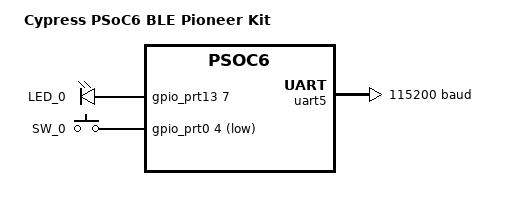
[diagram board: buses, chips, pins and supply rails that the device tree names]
/*
 * Copyright (c) 2018, Cypress
 * Copyright (c) 2020, ATL Electronics
 *
 * SPDX-License-Identifier: Apache-2.0
 */

/dts-v1/;

#include <cypress/psoc6_cm0.dtsi>

/ {
	model = "Cypress PSoC6 BLE Pioneer Kit";
	compatible = "cypress,cy8c6xx7_cm0p", "cypress,psoc6";

	aliases {
		sw0 = &user_bt;
		led0 = &user_led;
		uart-5 = &uart5;
	};

	chosen {
		zephyr,sram = &sram0;
		zephyr,flash = &flash0;
		zephyr,console = &uart5;
		zephyr,shell-uart = &uart5;
	};

	leds {
		compatible = "gpio-leds";
		user_led: led_0 {
			label = "LED_0";
			gpios = <&gpio_prt13 7 GPIO_ACTIVE_HIGH>;
		};
	};

	gpio_keys {
		compatible = "gpio-keys";

		user_bt: button_0 {
			label = "SW_0";
			gpios = <&gpio_prt0 4 (GPIO_PULL_UP | GPIO_ACTIVE_LOW)>;
		};
	};
};

&gpio_prt0 {
	status = "okay";
	interrupt-parent = <&intmux_ch20>;
};

&gpio_prt13 {
	status = "okay";
};

&uart5 {
	status = "okay";
	current-speed = <115200>;
};
